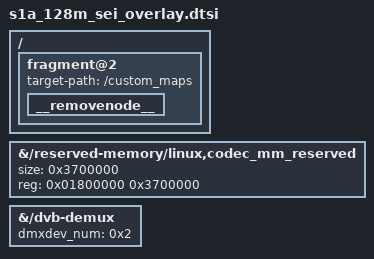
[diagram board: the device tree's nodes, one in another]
/dts-v1/;
/plugin/;

/ {
    fragment@0 {
        target-path = "/reserved-memory/linux,codec_mm_reserved";
        __overlay__ {
            size = <0x3700000>;
            reg = <0x01800000 0x3700000>;
        };
    };
    fragment@1 {
        target-path = "/dvb-demux";
        __overlay__ {
            dmxdev_num = <0x2>;
        };
    };
    fragment@2 {
        target-path = "/custom_maps";
        __removenode__ {
        };
    };
};
